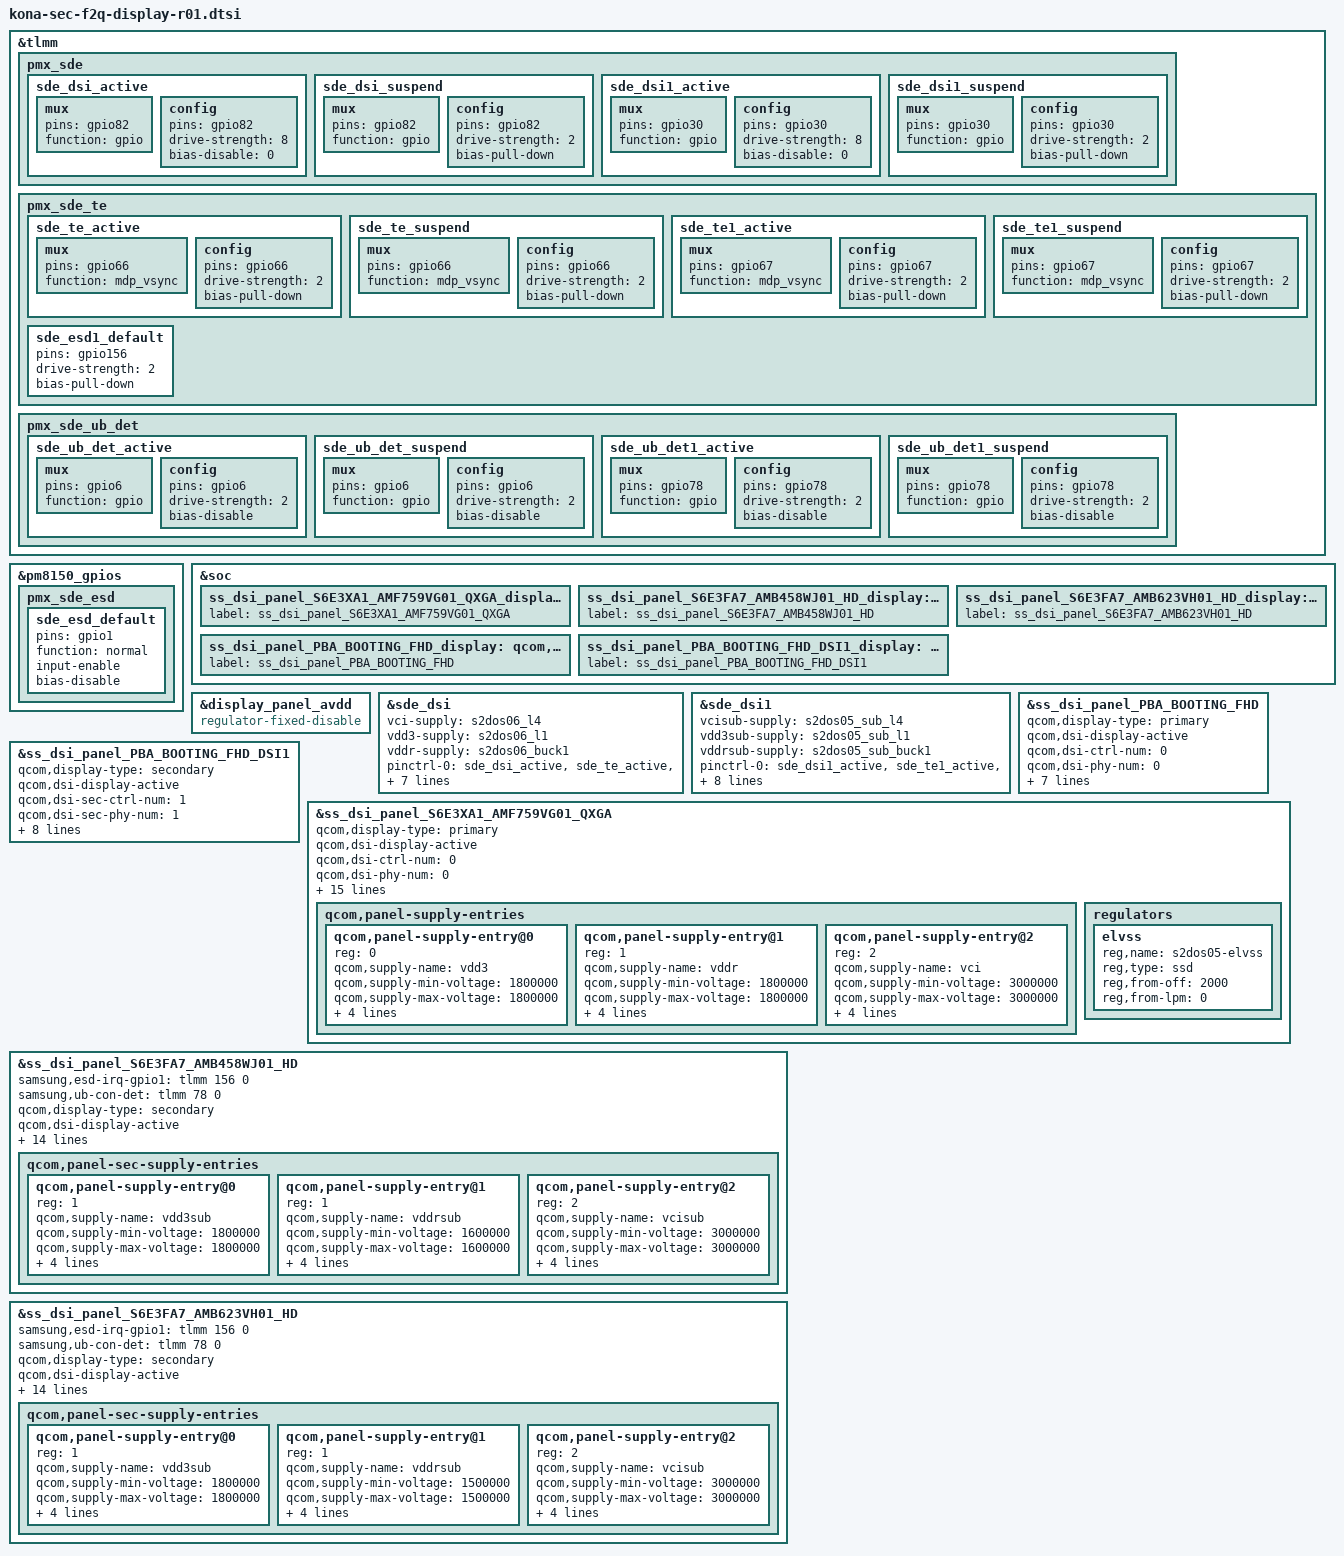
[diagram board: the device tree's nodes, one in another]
/* Copyright (c) 2016-2017, The Linux Foundation. All rights reserved.
 *
 * This program is free software; you can redistribute it and/or modify
 * it under the terms of the GNU General Public License version 2 and
 * only version 2 as published by the Free Software Foundation.
 *
 * This program is distributed in the hope that it will be useful,
 * but WITHOUT ANY WARRANTY; without even the implied warranty of
 * MERCHANTABILITY or FITNESS FOR A PARTICULAR PURPOSE.  See the
 * GNU General Public License for more details.
 */
#include "../../../../../../techpack/display/msm/samsung/MAFPC/ss_dsi_mafpc_cmd_XA1.dtsi"
#include "../../../../../../techpack/display/msm/samsung/SELF_DISPLAY/self_display_cmd_XA1.dtsi"
#include "../../../../../../techpack/display/msm/samsung/S6E3XA1_AMF759VG01/dsi_panel_S6E3XA1_AMF759VG01_qxga_octa_cmd.dtsi"
#include "../../../../../../techpack/display/msm/samsung/SELF_DISPLAY/self_display_cmd_FA7_AMB458WJ01.dtsi"
#include "../../../../../../techpack/display/msm/samsung/S6E3FA7_AMB458WJ01/dsi_panel_S6E3FA7_AMB458WJ01_hd_octa_cmd.dtsi"
#include "../../../../../../techpack/display/msm/samsung/SELF_DISPLAY/self_display_cmd_FA7_AMB623VH01.dtsi"
#include "../../../../../../techpack/display/msm/samsung/S6E3FA7_AMB623VH01/dsi_panel_S6E3FA7_AMB623VH01_hd_octa_cmd.dtsi"
#include "../../../../../../techpack/display/msm/samsung/PBA_BOOTING/dsi_panel_PBA_BOOTING_fhd_video.dtsi"
#include "../../../../../../techpack/display/msm/samsung/PBA_BOOTING_DSI1/dsi_panel_PBA_BOOTING_fhd_video_dsi1.dtsi"

&tlmm {
	pmx_sde: pmx_sde {
		sde_dsi_active: sde_dsi_active {
			mux {
				pins = "gpio82";
				function = "gpio";
			};

			config {
				pins = "gpio82";
				drive-strength = <8>;   /* 8 mA */
				bias-disable = <0>;   /* no pull */
			};
		};
		sde_dsi_suspend: sde_dsi_suspend {
			mux {
				pins = "gpio82";
				function = "gpio";
			};

			config {
				pins = "gpio82";
				drive-strength = <2>;   /* 2 mA */
				bias-pull-down;         /* PULL DOWN */
			};
		};

		sde_dsi1_active: sde_dsi1_active {
			mux {
				pins = "gpio30";
				function = "gpio";
			};

			config {
				pins = "gpio30";
				drive-strength = <8>;   /* 8 mA */
				bias-disable = <0>;   /* no pull */
			};
		};
		sde_dsi1_suspend: sde_dsi1_suspend {
			mux {
				pins = "gpio30";
				function = "gpio";
			};

			config {
				pins = "gpio30";
				drive-strength = <2>;   /* 2 mA */
				bias-pull-down;         /* PULL DOWN */
			};
		};
	};
	pmx_sde_te {
		sde_te_active: sde_te_active {
			mux {
				pins = "gpio66";
				function = "mdp_vsync";
			};

			config {
				pins = "gpio66";
				drive-strength = <2>;   /* 2 mA */
				bias-pull-down;         /* PULL DOWN */
			};
		};

		sde_te_suspend: sde_te_suspend {
			mux {
				pins = "gpio66";
				function = "mdp_vsync";
			};

			config {
				pins = "gpio66";
				drive-strength = <2>;   /* 2 mA */
				bias-pull-down;         /* PULL DOWN */
			};
		};

		sde_te1_active: sde_te1_active {
			mux {
				pins = "gpio67";
				function = "mdp_vsync";
			};

			config {
				pins = "gpio67";
				drive-strength = <2>;   /* 2 mA */
				bias-pull-down;         /* PULL DOWN */
			};
		};

		sde_te1_suspend: sde_te1_suspend {
			mux {
				pins = "gpio67";
				function = "mdp_vsync";
			};

			config {
				pins = "gpio67";
				drive-strength = <2>;   /* 2 mA */
				bias-pull-down;         /* PULL DOWN */
			};
		};

		sde_esd1_default: sde_esd1_default {
			pins = "gpio156";
			drive-strength = <2>;   /* 2 mA */
			bias-pull-down;         /* PULL DOWN */
		};

	};

	pmx_sde_ub_det {
		sde_ub_det_active: sde_ub_det_active {
			mux {
				pins = "gpio6";
				function = "gpio";
			};

			config {
				pins = "gpio6";
				drive-strength = <2>;   /* 2 mA */
				bias-disable;   /* no pull */
			};
		};

		sde_ub_det_suspend: sde_ub_det_suspend {
			mux {
				pins = "gpio6";
				function = "gpio";
			};

			config {
				pins = "gpio6";
				drive-strength = <2>;   /* 2 mA */
				bias-disable;   /* no pull */
			};
		};

		sde_ub_det1_active: sde_ub_det1_active {
			mux {
				pins = "gpio78";
				function = "gpio";
			};

			config {
				pins = "gpio78";
				drive-strength = <2>;   /* 2 mA */
				bias-disable;   /* no pull */
			};
		};

		sde_ub_det1_suspend: sde_ub_det1_suspend {
			mux {
				pins = "gpio78";
				function = "gpio";
			};

			config {
				pins = "gpio78";
				drive-strength = <2>;   /* 2 mA */
				bias-disable;   /* no pull */
			};
		};
	};
};

&pm8150_gpios {
	pmx_sde_esd {
		sde_esd_default: sde_esd_default {
			pins = "gpio1";
			function = "normal";
			input-enable;
			bias-disable;
		};
	};
};

&soc {
	/* winner main panel */
	ss_dsi_panel_S6E3XA1_AMF759VG01_QXGA_display: qcom,dsi-display@17 {
		label = "ss_dsi_panel_S6E3XA1_AMF759VG01_QXGA";
	};

	/* astar panel */
	ss_dsi_panel_S6E3FA7_AMB458WJ01_HD_display: qcom,dsi-display@18 {
		label = "ss_dsi_panel_S6E3FA7_AMB458WJ01_HD";
	};

	ss_dsi_panel_S6E3FA7_AMB623VH01_HD_display: qcom,dsi-display@19 {
		label = "ss_dsi_panel_S6E3FA7_AMB623VH01_HD";
	};

	/* PBA */
	ss_dsi_panel_PBA_BOOTING_FHD_display: qcom,dsi-display@20 {
		label = "ss_dsi_panel_PBA_BOOTING_FHD";
	};

	/* PBA for secondary display (DSI1) */
	ss_dsi_panel_PBA_BOOTING_FHD_DSI1_display: qcom,dsi-display@21 {
		label = "ss_dsi_panel_PBA_BOOTING_FHD_DSI1";
	};
};

/* display_panel_avdd node, in kona-sde-display.dtsi file, is gpio regualtor.
 * So, even SS doesn't enable the regulator, gpio61 is always registered as fixed regulator,
 * even it is for the other module, like audio i2c...
 * change compatible name to unused name, prevent to call probe of fixed regulator.
 */
&display_panel_avdd {
	compatible = "regulator-fixed-disable";
};

&sde_dsi {
	vci-supply = <&s2dos06_l4>;	/* VDD_MAIN_DDI_3P0, S2DOS05 LDO4 */
	vdd3-supply = <&s2dos06_l1>;	/* VDD_MAIN_DDI_1P8, S2DOS05 LDO1 */
	vddr-supply = <&s2dos06_buck1>;	/* VDD_MAIN_DDR_1P6, S2DOS05 buck */

	pinctrl-names = "panel_active", "panel_suspend";
	pinctrl-0 = <&sde_dsi_active &sde_te_active &sde_ub_det_active &sde_esd_default>;
	pinctrl-1 = <&sde_dsi_suspend &sde_te_suspend &sde_ub_det_suspend &sde_esd_default>;

	qcom,platform-te-gpio = <&tlmm 66 0>;

	qcom,dsi-display-list =
		<&ss_dsi_panel_S6E3XA1_AMF759VG01_QXGA
		&ss_dsi_panel_PBA_BOOTING_FHD>;
};

/* override display-list / supply for samsung panel */
&sde_dsi1 {

	vcisub-supply = <&s2dos05_sub_l4>;	/* VDD_MAIN_DDI_3P0, S2DOS05 LDO4 */
	vdd3sub-supply = <&s2dos05_sub_l1>;	/* VDD_MAIN_DDI_1P8, S2DOS05 LDO1 */
	vddrsub-supply = <&s2dos05_sub_buck1>;	/* VDD_MAIN_DDR_1P6, S2DOS05 buck */

	pinctrl-names = "panel_active", "panel_suspend";
	pinctrl-0 = <&sde_dsi1_active &sde_te1_active &sde_ub_det1_active &sde_esd1_default>;
	pinctrl-1 = <&sde_dsi1_suspend &sde_te1_suspend &sde_ub_det1_suspend  &sde_esd1_default>;

	qcom,platform-te-gpio = <&tlmm 67 0>;

	qcom,dsi-display-list =
		<&ss_dsi_panel_S6E3FA7_AMB458WJ01_HD
		&ss_dsi_panel_S6E3FA7_AMB623VH01_HD
		&ss_dsi_panel_PBA_BOOTING_FHD_DSI1>;
};

&ss_dsi_panel_PBA_BOOTING_FHD {
	qcom,display-type = "primary";
	qcom,dsi-display-active;

	qcom,dsi-ctrl-num = <0>;
	qcom,dsi-phy-num = <0>;
	qcom,dsi-select-clocks = "mux_byte_clk0", "mux_pixel_clk0";

	qcom,dsi-panel = <&ss_dsi_panel_PBA_BOOTING_FHD>;

	qcom,platform-reset-gpio = <&tlmm 82 0>;

	samsung,pll_ssc_disabled;
	samsung,ub-con-det = <&tlmm 6 0>;
	/* In pba booting mode, SS disables continuous splash mode.
	 * But QC recommended to enable splash mode as default..
	 * In case of splash enabled, it should not touch has_src_split  setitng..
	 * Refer to case 03756419.
	 */
	samsung,enable_splash_pba; /* enable continuous spalsh on PBA mode.. */
};

&ss_dsi_panel_PBA_BOOTING_FHD_DSI1 {
	qcom,display-type = "secondary";
	qcom,dsi-display-active;

	qcom,dsi-sec-ctrl-num = <1>;
	qcom,dsi-sec-phy-num = <1>;
	qcom,dsi-select-sec-clocks = "mux_byte_clk1", "mux_pixel_clk1";

	qcom,dsi-panel = <&ss_dsi_panel_PBA_BOOTING_FHD_DSI1>;

	qcom,platform-sec-reset-gpio = <&tlmm 30 0>;

	samsung,pll_ssc_disabled;
	samsung,ub-con-det = <&tlmm 78 0>; // SUB_DISP_CON_DET GPIO 78
	/* In pba booting mode, SS disables continuous splash mode.
	 * But QC recommended to enable splash mode as default..
	 * In case of splash enabled, it should not touch has_src_split  setitng..
	 * Refer to case 03756419.
	 */
	samsung,enable_splash_pba; /* enable continuous spalsh on PBA mode.. */
};

&ss_dsi_panel_S6E3XA1_AMF759VG01_QXGA {
	qcom,display-type = "primary";
	qcom,dsi-display-active;

	qcom,dsi-ctrl-num = <0>;
	qcom,dsi-phy-num = <0>;
	qcom,dsi-select-clocks = "mux_byte_clk0", "mux_pixel_clk0";

	qcom,dsi-panel = <&ss_dsi_panel_S6E3XA1_AMF759VG01_QXGA>;

	qcom,platform-reset-gpio = <&tlmm 82 0>;

	samsung,pll_ssc_disabled;
	/delete-property/ qcom,panel-mode-gpio;

	qcom,panel-supply-entries {
		#address-cells = <1>;
		#size-cells = <0>;

		qcom,panel-supply-entry@0 {
		    reg = <0>;
		    qcom,supply-name = "vdd3";
		    qcom,supply-min-voltage = <1800000>;
		    qcom,supply-max-voltage = <1800000>;
		    qcom,supply-enable-load = <100000>;
		    qcom,supply-disable-load = <100>;
		    qcom,supply-pre-on-sleep = <0>; /* unit is ms*/
		    qcom,supply-post-on-sleep = <0>;
		};

		qcom,panel-supply-entry@1 {
		    reg = <1>;
		    qcom,supply-name = "vddr";
		    qcom,supply-min-voltage = <1800000>;
		    qcom,supply-max-voltage = <1800000>;
		    qcom,supply-enable-load = <100000>;
		    qcom,supply-disable-load = <100>;
		    qcom,supply-pre-on-sleep = <0>; /* unit is ms*/
		    qcom,supply-post-on-sleep = <0>;
		};

		qcom,panel-supply-entry@2 {
		    reg = <2>;
		    qcom,supply-name = "vci";
		    qcom,supply-min-voltage = <3000000>;
		    qcom,supply-max-voltage = <3000000>;
		    qcom,supply-enable-load = <100000>;
		    qcom,supply-disable-load = <100>;
		    qcom,supply-pre-on-sleep = <0>; /* unit is ms*/
		    qcom,supply-post-on-sleep = <12>;
		};
	};
};

&ss_dsi_panel_S6E3XA1_AMF759VG01_QXGA {
	samsung,esd-irq-gpio1 = <&pm8150_gpios 1 0>; // MAIN_DISP_DET
	samsung,ub-con-det = <&tlmm 6 0>;  //MAIN_DISP_CON_DET
	samsung,delayed-display-on = <1>;

	samsung,lpm-power-control;
	samsung,lpm-power-control-supply-name = "vddr";
	samsung,lpm-power-control-supply-min-voltage = <1600000>;
	samsung,lpm-power-control-supply-max-voltage = <1600000>;
	/* should be controlled apart from qcom,panel-supply-entry */
	regulators {
		elvss {
			reg,name = "s2dos05-elvss";
			reg,type = "ssd";
			reg,from-off = <2000>;
			reg,from-lpm = <0>;
		};
	};
};

&ss_dsi_panel_S6E3FA7_AMB458WJ01_HD {
	samsung,esd-irq-gpio1 = <&tlmm 156 0>; // SUB_DISP_DET
	samsung,ub-con-det = <&tlmm 78 0>; // SUB_DISP_CON_DET

	qcom,display-type = "secondary";
	qcom,dsi-display-active;

	qcom,dsi-sec-ctrl-num = <1>;
	qcom,dsi-sec-phy-num = <1>;
	qcom,dsi-select-sec-clocks = "mux_byte_clk1", "mux_pixel_clk1";

	qcom,dsi-panel = <&ss_dsi_panel_S6E3FA7_AMB458WJ01_HD>;

	qcom,platform-sec-reset-gpio = <&tlmm 30 0>;

	samsung,pll_ssc_disabled;
	/delete-property/ qcom,panel-mode-gpio;

	qcom,panel-sec-supply-entries {
		#address-cells = <1>;
		#size-cells = <0>;

		qcom,panel-supply-entry@0 {
		    reg = <1>;
		    qcom,supply-name = "vdd3sub";
		    qcom,supply-min-voltage = <1800000>;
		    qcom,supply-max-voltage = <1800000>;
		    qcom,supply-enable-load = <100000>;
		    qcom,supply-disable-load = <100>;
		    qcom,supply-pre-on-sleep = <0>; /* unit is ms*/
		    qcom,supply-post-on-sleep = <0>;
		};

		qcom,panel-supply-entry@1 {
		    reg = <1>;
		    qcom,supply-name = "vddrsub";
		    qcom,supply-min-voltage = <1600000>;
		    qcom,supply-max-voltage = <1600000>;
		    qcom,supply-enable-load = <100000>;
		    qcom,supply-disable-load = <100>;
		    qcom,supply-pre-on-sleep = <0>; /* unit is ms*/
		    qcom,supply-post-on-sleep = <0>;
		};

		qcom,panel-supply-entry@2 {
		    reg = <2>;
		    qcom,supply-name = "vcisub";
		    qcom,supply-min-voltage = <3000000>;
		    qcom,supply-max-voltage = <3000000>;
		    qcom,supply-enable-load = <100000>;
		    qcom,supply-disable-load = <100>;
		    qcom,supply-pre-on-sleep = <0>; /* unit is ms*/
		    qcom,supply-post-on-sleep = <10>;
		};
	};
};

&ss_dsi_panel_S6E3FA7_AMB458WJ01_HD {
	samsung,lpm-power-control;
	samsung,lpm-power-control-supply-name = "vddrsub";
	samsung,lpm-power-control-supply-min-voltage = <1500000>;
	samsung,lpm-power-control-supply-max-voltage = <1500000>;
};

&ss_dsi_panel_S6E3FA7_AMB623VH01_HD {
	samsung,esd-irq-gpio1 = <&tlmm 156 0>; // SUB_DISP_DET
	samsung,ub-con-det = <&tlmm 78 0>; // SUB_DISP_CON_DET

	qcom,display-type = "secondary";
	qcom,dsi-display-active;

	qcom,dsi-sec-ctrl-num = <1>;
	qcom,dsi-sec-phy-num = <1>;
	qcom,dsi-select-sec-clocks = "mux_byte_clk1", "mux_pixel_clk1";

	qcom,dsi-panel = <&ss_dsi_panel_S6E3FA7_AMB623VH01_HD>;

	qcom,platform-sec-reset-gpio = <&tlmm 30 0>;

	samsung,pll_ssc_disabled;
	/delete-property/ qcom,panel-mode-gpio;

	qcom,panel-sec-supply-entries {
		#address-cells = <1>;
		#size-cells = <0>;

		qcom,panel-supply-entry@0 {
		    reg = <1>;
		    qcom,supply-name = "vdd3sub";
		    qcom,supply-min-voltage = <1800000>;
		    qcom,supply-max-voltage = <1800000>;
		    qcom,supply-enable-load = <100000>;
		    qcom,supply-disable-load = <100>;
		    qcom,supply-pre-on-sleep = <0>; /* unit is ms*/
		    qcom,supply-post-on-sleep = <0>;
		};

		qcom,panel-supply-entry@1 {
		    reg = <1>;
		    qcom,supply-name = "vddrsub";
		    qcom,supply-min-voltage = <1500000>;
		    qcom,supply-max-voltage = <1500000>;
		    qcom,supply-enable-load = <100000>;
		    qcom,supply-disable-load = <100>;
		    qcom,supply-pre-on-sleep = <0>; /* unit is ms*/
		    qcom,supply-post-on-sleep = <0>;
		};

		qcom,panel-supply-entry@2 {
		    reg = <2>;
		    qcom,supply-name = "vcisub";
		    qcom,supply-min-voltage = <3000000>;
		    qcom,supply-max-voltage = <3000000>;
		    qcom,supply-enable-load = <100000>;
		    qcom,supply-disable-load = <100>;
		    qcom,supply-pre-on-sleep = <0>; /* unit is ms*/
		    qcom,supply-post-on-sleep = <10>;
		};
	};
};

&ss_dsi_panel_S6E3FA7_AMB623VH01_HD {
	samsung,lpm-power-control;
	samsung,lpm-power-control-supply-name = "vddrsub";
	samsung,lpm-power-control-supply-min-voltage = <1500000>;
	samsung,lpm-power-control-supply-max-voltage = <1500000>;
};
